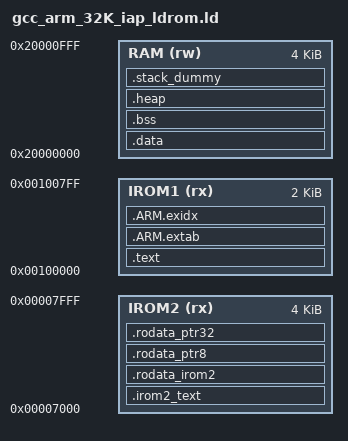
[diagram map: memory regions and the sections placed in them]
MEMORY
{
    IROM2 (rx) : ORIGIN = 0x00007000, LENGTH = 0x1000    /* 4KB */
    IROM1 (rx) : ORIGIN = 0x00100000, LENGTH = 0x800     /* 2KB */
    RAM   (rw) : ORIGIN = 0x20000000, LENGTH = 0x1000    /* 4KB */
}

/* GROUP(libgcc.a libc.a libm.a libnosys.a) */
GROUP(libgcc.a)

ENTRY(Reset_Handler)

SECTIONS
{
    /* IROM2：手動標記放置大函式 / 少用函式 */
    .irom2_text :
    {
        __irom2_text_start = .;
        KEEP(*(.irom2_text*))
        __irom2_text_end = .;
    } > IROM2 AT > IROM2

    /* IROM2：專用常數與指標陣列段 */
    .rodata_irom2 :
    {
        __rodata_irom2_start = .;
        *(.rodata_irom2*)
        __rodata_irom2_end = .;
    } > IROM2 AT > IROM2

    /* IROM2：放 pointer 陣列 (uint8_t* / uint32_t*) */
    .rodata_ptr8 :
    {
        *(.rodata_ptr8*)
    } > IROM2 AT > IROM2

    /* 放 uint32_t 指標陣列 */
    .rodata_ptr32 :
    {
        *(.rodata_ptr32*)
    } > IROM2 AT > IROM2

    /* 主程式碼優先放 IROM1 */
    .text :
    {
        KEEP(*(.vectors))
        __Vectors_End = .;
        __Vectors_Size = __Vectors_End - __Vectors;
        __end__ = .;

        *(.text*)         /* 主要程式碼放 IROM1 */
        *(.rodata*)

        KEEP(*(.init))
        KEEP(*(.fini))

        *crtbegin.o(.ctors)
        *crtbegin?.o(.ctors)
        *(EXCLUDE_FILE(*crtend?.o *crtend.o) .ctors)
        *(SORT(.ctors.*))
        *(.ctors)

        *crtbegin.o(.dtors)
        *crtbegin?.o(.dtors)
        *(EXCLUDE_FILE(*crtend?.o *crtend.o) .dtors)
        *(SORT(.dtors.*))
        *(.dtors)

        KEEP(*(.eh_frame*))
    } > IROM1 AT > IROM1

    /* Exception unwinding tables */
    .ARM.extab :
    {
        *(.ARM.extab* .gnu.linkonce.armextab.*)
    } > IROM1

    __exidx_start = .;
    .ARM.exidx :
    {
        *(.ARM.exidx* .gnu.linkonce.armexidx.*)
    } > IROM1
    __exidx_end = .;




    
	/* To copy multiple ROM to RAM sections,
	 * uncomment .copy.table section and,
	 * define __STARTUP_COPY_MULTIPLE in startup_ARMCMx.S */
	/*
	.copy.table :
	{
		. = ALIGN(4);
		__copy_table_start__ = .;
		LONG (__etext)
		LONG (__data_start__)
		LONG (__data_end__ - __data_start__)
		LONG (__etext2)
		LONG (__data2_start__)
		LONG (__data2_end__ - __data2_start__)
		__copy_table_end__ = .;
	} > FLASH
	*/

	/* To clear multiple BSS sections,
	 * uncomment .zero.table section and,
	 * define __STARTUP_CLEAR_BSS_MULTIPLE in startup_ARMCMx.S */
	/*
	.zero.table :
	{
		. = ALIGN(4);
		__zero_table_start__ = .;
		LONG (__bss_start__)
		LONG (__bss_end__ - __bss_start__)
		LONG (__bss2_start__)
		LONG (__bss2_end__ - __bss2_start__)
		__zero_table_end__ = .;
	} > FLASH
	*/

	__etext = .;

    /* Data section */
    .data : AT (__etext)
    {
        __data_start__ = .;
        *(vtable)
        *(.data*)

		. = ALIGN(4);
		/* preinit data */
		PROVIDE_HIDDEN (__preinit_array_start = .);
		KEEP(*(.preinit_array))
		PROVIDE_HIDDEN (__preinit_array_end = .);

		. = ALIGN(4);
		/* init data */
		PROVIDE_HIDDEN (__init_array_start = .);
		KEEP(*(SORT(.init_array.*)))
		KEEP(*(.init_array))
		PROVIDE_HIDDEN (__init_array_end = .);


		. = ALIGN(4);
		/* finit data */
		PROVIDE_HIDDEN (__fini_array_start = .);
		KEEP(*(SORT(.fini_array.*)))
		KEEP(*(.fini_array))
		PROVIDE_HIDDEN (__fini_array_end = .);

		KEEP(*(.jcr*))
		. = ALIGN(4);
		/* All data end */
		__data_end__ = .;

	} > RAM

    /* BSS section */
    .bss :
    {
        . = ALIGN(4);
        __bss_start__ = .;
        *(.bss*)
        *(COMMON)
        . = ALIGN(4);
        __bss_end__ = .;
    } > RAM

    /* Heap */
    .heap (COPY):
    {
        __HeapBase = .;
        __end__ = .;
        end = __end__;
        KEEP(*(.heap*))
        __HeapLimit = .;
    } > RAM

	/* .stack_dummy section doesn't contains any symbols. It is only
	 * used for linker to calculate size of stack sections, and assign
	 * values to stack symbols later */
	.stack_dummy (COPY):
	{
		KEEP(*(.stack*))
	} > RAM

	/* Set stack top to end of RAM, and stack limit move down by
	 * size of stack_dummy section */
	__StackTop = ORIGIN(RAM) + LENGTH(RAM);
	__StackLimit = __StackTop - SIZEOF(.stack_dummy);
	PROVIDE(__stack = __StackTop);

	/* Check if data + heap + stack exceeds RAM limit */
	ASSERT(__StackLimit >= __HeapLimit, "region RAM overflowed with stack")
}
